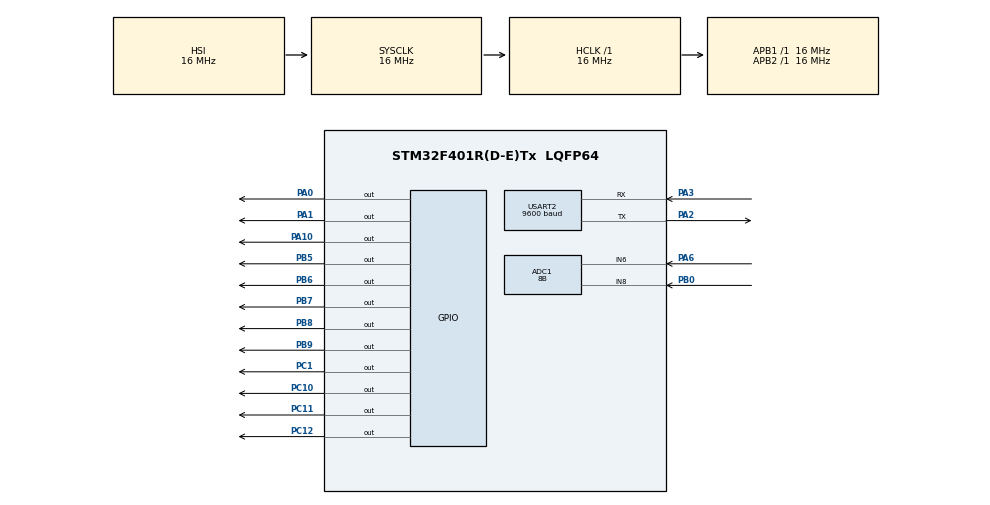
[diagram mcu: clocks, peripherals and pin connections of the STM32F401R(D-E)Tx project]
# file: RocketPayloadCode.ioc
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ADC1.Channel-1\#ChannelRegularConversion=ADC_CHANNEL_6
ADC1.ClockPrescaler=ADC_CLOCK_SYNC_PCLK_DIV8
ADC1.ContinuousConvMode=DISABLE
ADC1.NbrOfConversion=1
ADC1.NbrOfConversionFlag=1
ADC1.Rank-1\#ChannelRegularConversion=1
ADC1.Resolution=ADC_RESOLUTION_8B
ADC1.SamplingTime-1\#ChannelRegularConversion=ADC_SAMPLETIME_28CYCLES
ADC1.master=1
Dma.Request0=USART2_RX
Dma.USART2_RX.0.Direction=DMA_PERIPH_TO_MEMORY
Dma.USART2_RX.0.FIFOMode=DMA_FIFOMODE_DISABLE
Dma.USART2_RX.0.Instance=DMA1_Stream5
Dma.USART2_RX.0.MemDataAlignment=DMA_MDATAALIGN_BYTE
Dma.USART2_RX.0.MemInc=DMA_MINC_ENABLE
Dma.USART2_RX.0.Mode=DMA_CIRCULAR
Dma.USART2_RX.0.PeriphDataAlignment=DMA_PDATAALIGN_BYTE
Dma.USART2_RX.0.PeriphInc=DMA_PINC_DISABLE
Dma.USART2_RX.0.Priority=DMA_PRIORITY_LOW
FREERTOS.Tasks01=defaultTask,0,128,StartDefaultTask,Default,NULL,Dynamic,NULL,NULL
Mcu.Family=STM32F4
Mcu.Name=STM32F401R(D-E)Tx
Mcu.Package=LQFP64
NVIC.DMA1_Stream5_IRQn=true\:5\:0\:false\:false\:true\:true\:false\:true
NVIC.PriorityGroup=NVIC_PRIORITYGROUP_4
NVIC.TIM1_UP_TIM10_IRQn=true\:0\:0\:false\:false\:true\:false\:false\:true
NVIC.TimeBase=TIM1_UP_TIM10_IRQn
NVIC.TimeBaseIP=TIM1
NVIC.USART2_IRQn=true\:5\:0\:false\:false\:true\:true\:true\:true
PA0-WKUP.Signal=GPIO_Output
PA1.Signal=GPIO_Output
PA10.Signal=GPIO_Output
PA13.Mode=JTAG_5_pins
PA13.Signal=SYS_JTMS-SWDIO
PA14.Mode=JTAG_5_pins
PA14.Signal=SYS_JTCK-SWCLK
PA15.Mode=JTAG_5_pins
PA15.Signal=SYS_JTDI
PA2.Mode=Asynchronous
PA2.Signal=USART2_TX
PA3.Mode=Asynchronous
PA3.Signal=USART2_RX
PA6.Signal=ADCx_IN6
PB0.Signal=ADCx_IN8
PB3.Mode=JTAG_5_pins
PB3.Signal=SYS_JTDO-SWO
PB4.Mode=JTAG_5_pins
PB4.Signal=SYS_JTRST
PB5.Signal=GPIO_Output
PB6.Signal=GPIO_Output
PB7.Signal=GPIO_Output
PB8.Signal=GPIO_Output
PB9.Signal=GPIO_Output
PC1.Signal=GPIO_Output
PC10.Signal=GPIO_Output
PC11.Signal=GPIO_Output
PC12.Signal=GPIO_Output
ProjectManager.HeapSize=0x200
ProjectManager.StackSize=0x400
ProjectManager.TargetToolchain=STM32CubeIDE
RCC.AHBFreq_Value=16000000
RCC.APB1Freq_Value=16000000
RCC.APB1TimFreq_Value=16000000
RCC.APB2Freq_Value=16000000
RCC.APB2TimFreq_Value=16000000
RCC.CortexFreq_Value=16000000
RCC.HCLKFreq_Value=16000000
RCC.HSE_VALUE=25000000
RCC.HSI_VALUE=16000000
RCC.LSE_VALUE=32768
RCC.SYSCLKFreq_VALUE=16000000
RCC.VCOOutputFreq_Value=192000000
SH.ADCx_IN6.0=ADC1_IN6,IN6
SH.ADCx_IN8.0=ADC1_IN8,IN8
USART2.BaudRate=9600
USART2.VirtualMode=VM_ASYNC
VP_FREERTOS_VS_CMSIS_V1.Mode=CMSIS_V1
VP_SYS_VS_tim1.Mode=TIM1
board=custom

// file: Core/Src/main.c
/* USER CODE BEGIN Header */
/**
  ******************************************************************************
  * @file           : main.c
  * @brief          : Main program body
  ******************************************************************************
  * @attention
  *
  * <h2><center>&copy; Copyright (c) 2020 STMicroelectronics.
  * All rights reserved.</center></h2>
  *
  * This software component is licensed by ST under BSD 3-Clause license,
  * the "License"; You may not use this file except in compliance with the
  * License. You may obtain a copy of the License at:
  *                        opensource.org/licenses/BSD-3-Clause
  *
  ******************************************************************************
  */
/* USER CODE END Header */

#include "main.h"
#include "cmsis_os.h"

/* USER CODE BEGIN Includes */
#include "PeripheralControl.h"
//#include "TaskEntryPoints.h"
/* USER CODE END Includes */

ADC_HandleTypeDef hadc1;

UART_HandleTypeDef huart2;
DMA_HandleTypeDef hdma_usart2_rx;

osThreadId defaultTaskHandle;
/* USER CODE BEGIN PV */
osThreadId motorControlTaskHandle;
uint8_t BT_Buf = '\0';
/* USER CODE END PV */

void SystemClock_Config(void);
static void MX_GPIO_Init(void);
static void MX_DMA_Init(void);
static void MX_ADC1_Init(void);
static void MX_USART2_UART_Init(void);
void StartDefaultTask(void const * argument);
void vMotor_Control(void const * argument);

int main(void)
{

  /* MCU Configuration--------------------------------------------------------*/

  /* Reset of all peripherals, Initializes the Flash interface and the Systick. */
  HAL_Init();

  /* Configure the system clock */
  SystemClock_Config();

  /* Initialize all configured peripherals */
  MX_GPIO_Init();
  MX_DMA_Init();
  MX_ADC1_Init();
  MX_USART2_UART_Init();
  /* USER CODE BEGIN 2 */
  //uint8_t temp = 0;
  //uint8_t volts = 0;
  /* USER CODE END 2 */

  /* Create the thread(s) */
  /* definition and creation of defaultTask */
  osThreadDef(defaultTask, StartDefaultTask, osPriorityNormal, 0, 128);
  defaultTaskHandle = osThreadCreate(osThread(defaultTask), NULL);

  /* USER CODE BEGIN RTOS_THREADS */
  /* add threads, ... */
  if( xTaskCreate( vMotor_Control, /* Pointer to the function that implements the task */
			       "motorControl", /* Text name for the task. This is only to facilitate debugging */
			       128, /* Stack depth */
			       NULL, /* pointer to the arguments object */
			       1, /* This task will run at priority 1. */
			       &motorControlTaskHandle /* This example does not use the task handle. */
			       ) != pdPASS){
	  Error_Handler();
  }
  /* USER CODE END RTOS_THREADS */

  /* Start scheduler */
  osKernelStart();

  /* We should never get here as control is now taken by the scheduler */
  /* Infinite loop */
  while (1)
  {

    /* USER CODE BEGIN 3 */
	//temp = (uint8_t)GetTempVal(hadc1, adc_config);
//	volts = (uint8_t)GetVoltsValueADC(hadc1, adc_config);
//
//	HAL_UART_Transmit(&huart2, &temp, sizeof(temp), 10);
//	HAL_Delay(1000);
//
//	if(BT_Buf == 'n')
//		WriteMotor(rear_rev, GPIO_PIN_SET);
//	if(BT_Buf == 'f')
//		WriteMotor(rear_fwd, GPIO_PIN_RESET);
//
//	HAL_Delay(1000);
  }
  /* USER CODE END 3 */
}

 /******************************************************************************/
 /*          STM32F401RE RTOS functions		         			               */
 /******************************************************************************/

void StartDefaultTask(void const * argument)
{
  for(;;)
  {
    osDelay(1);
  }
}

 /**
   * @brief This function handles Bluetooth input commands and the corresponding motor control.
 */
 void vMotor_Control(void const * argument)
 {

	while (1) {
		HAL_UART_Receive_DMA(&huart2, &BT_Buf, sizeof(BT_Buf));

		switch(BT_Buf){
		case 'x':
			ResetMotors();
			break;
		case 'i':
			WriteMotor(rear_fwd, GPIO_PIN_RESET);
			WriteMotor(front_fwd, GPIO_PIN_RESET);
			WriteMotor(rear_rev, GPIO_PIN_SET);
			WriteMotor(front_rev, GPIO_PIN_SET);
			break;
		case 'o':
			WriteMotor(rear_rev, GPIO_PIN_RESET);
			WriteMotor(front_rev, GPIO_PIN_RESET);
			WriteMotor(rear_fwd, GPIO_PIN_SET);
			WriteMotor(front_fwd, GPIO_PIN_SET);
			break;
		case 'u':
			WriteMotor(left_rev, GPIO_PIN_RESET);
			WriteMotor(right_rev, GPIO_PIN_RESET);
			WriteMotor(left_fwd, GPIO_PIN_SET);
			WriteMotor(right_fwd, GPIO_PIN_SET);
			break;
		case 'd':
			WriteMotor(left_fwd, GPIO_PIN_RESET);
			WriteMotor(right_fwd, GPIO_PIN_RESET);
			WriteMotor(left_rev, GPIO_PIN_SET);
			WriteMotor(right_rev, GPIO_PIN_SET);
			break;
		case 'l':
			WriteMotor(left_fwd, GPIO_PIN_RESET);
			WriteMotor(right_rev, GPIO_PIN_RESET);
			WriteMotor(left_rev, GPIO_PIN_SET);
			WriteMotor(right_fwd, GPIO_PIN_SET);
			break;
		case 'r':
			WriteMotor(left_rev, GPIO_PIN_RESET);
			WriteMotor(right_fwd, GPIO_PIN_RESET);
			WriteMotor(left_fwd, GPIO_PIN_SET);
			WriteMotor(right_rev, GPIO_PIN_SET);
			break;
		default:
			ResetMotors();
			break;
		}

		osDelay(50);
	}

 }

void SystemClock_Config(void)
{
  RCC_OscInitTypeDef RCC_OscInitStruct = {0};
  RCC_ClkInitTypeDef RCC_ClkInitStruct = {0};

  /** Configure the main internal regulator output voltage
  */
  __HAL_RCC_PWR_CLK_ENABLE();
  __HAL_PWR_VOLTAGESCALING_CONFIG(PWR_REGULATOR_VOLTAGE_SCALE2);
  /** Initializes the CPU, AHB and APB busses clocks
  */
  RCC_OscInitStruct.OscillatorType = RCC_OSCILLATORTYPE_HSI;
  RCC_OscInitStruct.HSIState = RCC_HSI_ON;
  RCC_OscInitStruct.HSICalibrationValue = RCC_HSICALIBRATION_DEFAULT;
  RCC_OscInitStruct.PLL.PLLState = RCC_PLL_NONE;
  if (HAL_RCC_OscConfig(&RCC_OscInitStruct) != HAL_OK)
  {
    Error_Handler();
  }
  /** Initializes the CPU, AHB and APB busses clocks
  */
  RCC_ClkInitStruct.ClockType = RCC_CLOCKTYPE_HCLK|RCC_CLOCKTYPE_SYSCLK
                              |RCC_CLOCKTYPE_PCLK1|RCC_CLOCKTYPE_PCLK2;
  RCC_ClkInitStruct.SYSCLKSource = RCC_SYSCLKSOURCE_HSI;
  RCC_ClkInitStruct.AHBCLKDivider = RCC_SYSCLK_DIV1;
  RCC_ClkInitStruct.APB1CLKDivider = RCC_HCLK_DIV1;
  RCC_ClkInitStruct.APB2CLKDivider = RCC_HCLK_DIV1;

  if (HAL_RCC_ClockConfig(&RCC_ClkInitStruct, FLASH_LATENCY_0) != HAL_OK)
  {
    Error_Handler();
  }
}

static void MX_ADC1_Init(void)
{

  ADC_ChannelConfTypeDef sConfig = {0};

  /** Configure the global features of the ADC (Clock, Resolution, Data Alignment and number of conversion)
  */
  hadc1.Instance = ADC1;
  hadc1.Init.ClockPrescaler = ADC_CLOCK_SYNC_PCLK_DIV8;
  hadc1.Init.Resolution = ADC_RESOLUTION_8B;
  hadc1.Init.ScanConvMode = DISABLE;
  hadc1.Init.ContinuousConvMode = DISABLE;
  hadc1.Init.DiscontinuousConvMode = DISABLE;
  hadc1.Init.ExternalTrigConvEdge = ADC_EXTERNALTRIGCONVEDGE_NONE;
  hadc1.Init.ExternalTrigConv = ADC_SOFTWARE_START;
  hadc1.Init.DataAlign = ADC_DATAALIGN_RIGHT;
  hadc1.Init.NbrOfConversion = 1;
  hadc1.Init.DMAContinuousRequests = DISABLE;
  hadc1.Init.EOCSelection = ADC_EOC_SINGLE_CONV;
  if (HAL_ADC_Init(&hadc1) != HAL_OK)
  {
    Error_Handler();
  }
  /** Configure for the selected ADC regular channel its corresponding rank in the sequencer and its sample time.
  */
  sConfig.Channel = ADC_CHANNEL_6;
  sConfig.Rank = 1;
  sConfig.SamplingTime = ADC_SAMPLETIME_28CYCLES;
  if (HAL_ADC_ConfigChannel(&hadc1, &sConfig) != HAL_OK)
  {
    Error_Handler();
  }
  /* USER CODE BEGIN ADC1_Init 2 */
  //adc_config = sConfig;
  /* USER CODE END ADC1_Init 2 */

}

static void MX_USART2_UART_Init(void)
{

  huart2.Instance = USART2;
  huart2.Init.BaudRate = 9600;
  huart2.Init.WordLength = UART_WORDLENGTH_8B;
  huart2.Init.StopBits = UART_STOPBITS_1;
  huart2.Init.Parity = UART_PARITY_NONE;
  huart2.Init.Mode = UART_MODE_TX_RX;
  huart2.Init.HwFlowCtl = UART_HWCONTROL_NONE;
  huart2.Init.OverSampling = UART_OVERSAMPLING_16;
  if (HAL_UART_Init(&huart2) != HAL_OK)
  {
    Error_Handler();
  }

}

static void MX_DMA_Init(void)
{

  /* DMA controller clock enable */
  __HAL_RCC_DMA1_CLK_ENABLE();

  /* DMA interrupt init */
  /* DMA1_Stream5_IRQn interrupt configuration */
  HAL_NVIC_SetPriority(DMA1_Stream5_IRQn, 5, 0);
  HAL_NVIC_EnableIRQ(DMA1_Stream5_IRQn);

}

static void MX_GPIO_Init(void)
{
  GPIO_InitTypeDef GPIO_InitStruct = {0};

  /* GPIO Ports Clock Enable */
  __HAL_RCC_GPIOC_CLK_ENABLE();
  __HAL_RCC_GPIOA_CLK_ENABLE();
  __HAL_RCC_GPIOB_CLK_ENABLE();

  /*Configure GPIO pin Output Level */
  HAL_GPIO_WritePin(GPIOC, GPIO_PIN_1|GPIO_PIN_10|GPIO_PIN_11|GPIO_PIN_12, GPIO_PIN_RESET);

  /*Configure GPIO pin Output Level */
  HAL_GPIO_WritePin(GPIOA, GPIO_PIN_0|GPIO_PIN_1|GPIO_PIN_10, GPIO_PIN_RESET);

  /*Configure GPIO pin Output Level */
  HAL_GPIO_WritePin(GPIOB, GPIO_PIN_5|GPIO_PIN_6|GPIO_PIN_7|GPIO_PIN_8
                          |GPIO_PIN_9, GPIO_PIN_RESET);

  /*Configure GPIO pins : PC1 PC10 PC11 PC12 */
  GPIO_InitStruct.Pin = GPIO_PIN_1|GPIO_PIN_10|GPIO_PIN_11|GPIO_PIN_12;
  GPIO_InitStruct.Mode = GPIO_MODE_OUTPUT_PP;
  GPIO_InitStruct.Pull = GPIO_NOPULL;
  GPIO_InitStruct.Speed = GPIO_SPEED_FREQ_LOW;
  HAL_GPIO_Init(GPIOC, &GPIO_InitStruct);

  /*Configure GPIO pins : PA0 PA1 PA10 */
  GPIO_InitStruct.Pin = GPIO_PIN_0|GPIO_PIN_1|GPIO_PIN_10;
  GPIO_InitStruct.Mode = GPIO_MODE_OUTPUT_PP;
  GPIO_InitStruct.Pull = GPIO_NOPULL;
  GPIO_InitStruct.Speed = GPIO_SPEED_FREQ_LOW;
  HAL_GPIO_Init(GPIOA, &GPIO_InitStruct);

  /*Configure GPIO pins : PB5 PB6 PB7 PB8
                           PB9 */
  GPIO_InitStruct.Pin = GPIO_PIN_5|GPIO_PIN_6|GPIO_PIN_7|GPIO_PIN_8
                          |GPIO_PIN_9;
  GPIO_InitStruct.Mode = GPIO_MODE_OUTPUT_PP;
  GPIO_InitStruct.Pull = GPIO_NOPULL;
  GPIO_InitStruct.Speed = GPIO_SPEED_FREQ_LOW;
  HAL_GPIO_Init(GPIOB, &GPIO_InitStruct);

}

/* USER CODE BEGIN 4 */
void HAL_UART_RxCpltCallback(UART_HandleTypeDef *huart){
	UNUSED(huart);

	HAL_UART_Transmit(&huart2, &BT_Buf, 1, 10);
}
/* USER CODE END 4 */

 /**
  * @brief  Period elapsed callback in non blocking mode
  * @note   This function is called  when TIM1 interrupt took place, inside
  * HAL_TIM_IRQHandler(). It makes a direct call to HAL_IncTick() to increment
  * a global variable "uwTick" used as application time base.
  * @param  htim : TIM handle
  * @retval None
  */
void HAL_TIM_PeriodElapsedCallback(TIM_HandleTypeDef *htim)
{
  if (htim->Instance == TIM1) {
    HAL_IncTick();
  }
}

void Error_Handler(void)
{
}

/************************ (C) COPYRIGHT STMicroelectronics *****END OF FILE****/
